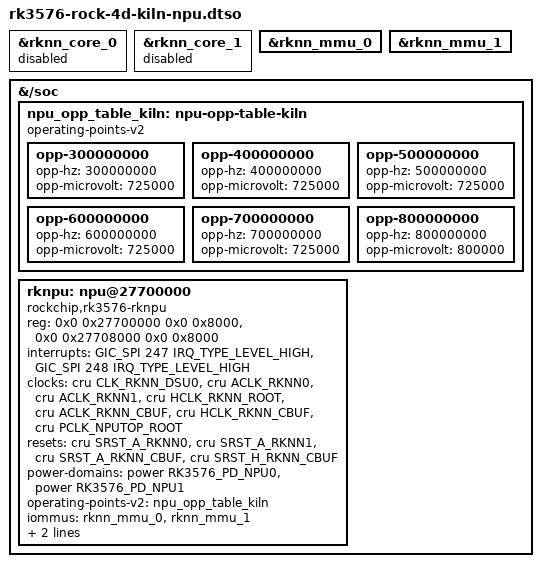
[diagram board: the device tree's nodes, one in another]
// SPDX-License-Identifier: (GPL-2.0-only OR MIT)
/*
 * Kiln NPU overlay for Radxa ROCK 4D (RK3576) on a mainline / Armbian kernel.
 *
 * Turns the board's open "rocket" NPU (rknn_core_0/1) OFF and adds the single
 * vendor-shaped npu@27700000 that the out-of-tree vendor rknpu (v0.9.8) driver
 * binds, so librkllmrt / RKLLM can run LLMs on the NPU. It REUSES the base DT's
 * rknn_mmu_0/1 IOMMU nodes (same hardware, same clocks/power-domain as the
 * vendor MMUs) instead of declaring duplicates.
 *
 * Build:  dtc -@ -I dts -O dtb -o rk3576-rock-4d-kiln-npu.dtbo \
 *              rk3576-rock-4d-kiln-npu.dtso    (cpp-preprocessed for the headers)
 * Armbian: copy the .dtbo to /boot/dtb/rockchip/overlay/ (or /boot/overlay-user/)
 *          and add its name to `user_overlays=` in /boot/armbianEnv.txt.
 *
 * Requires: the base DT to expose the labels &rknn_core_0/1, &rknn_mmu_0/1,
 * &cru, &power, &vdd_npu_s0 (mainline rk3576.dtsi + rk3576-rock-4d.dts do).
 */
/dts-v1/;
/plugin/;

#include <dt-bindings/clock/rockchip,rk3576-cru.h>
#include <dt-bindings/interrupt-controller/arm-gic.h>
#include <dt-bindings/interrupt-controller/irq.h>
#include <dt-bindings/power/rockchip,rk3576-power.h>
#include <dt-bindings/reset/rockchip,rk3576-cru.h>

/* Turn the open rocket NPU cores off; the vendor rknpu drives this hardware. */
&rknn_core_0 { status = "disabled"; };
&rknn_core_1 { status = "disabled"; };

/* Reuse the base MMU nodes as the vendor NPU's two IOMMUs (one per core). */
&rknn_mmu_0 { status = "okay"; };
&rknn_mmu_1 { status = "okay"; };

&{/soc} {
	npu_opp_table_kiln: npu-opp-table-kiln {
		compatible = "operating-points-v2";
		opp-300000000 { opp-hz = /bits/ 64 <300000000>; opp-microvolt = <725000>; };
		opp-400000000 { opp-hz = /bits/ 64 <400000000>; opp-microvolt = <725000>; };
		opp-500000000 { opp-hz = /bits/ 64 <500000000>; opp-microvolt = <725000>; };
		opp-600000000 { opp-hz = /bits/ 64 <600000000>; opp-microvolt = <725000>; };
		opp-700000000 { opp-hz = /bits/ 64 <700000000>; opp-microvolt = <725000>; };
		opp-800000000 { opp-hz = /bits/ 64 <800000000>; opp-microvolt = <800000>; };
	};

	rknpu: npu@27700000 {
		compatible = "rockchip,rk3576-rknpu";
		reg = <0x0 0x27700000 0x0 0x8000>,
		      <0x0 0x27708000 0x0 0x8000>;
		interrupts = <GIC_SPI 247 IRQ_TYPE_LEVEL_HIGH>,
			     <GIC_SPI 248 IRQ_TYPE_LEVEL_HIGH>;
		interrupt-names = "npu0_irq", "npu1_irq";
		clocks = <&cru CLK_RKNN_DSU0>, <&cru ACLK_RKNN0>,
			 <&cru ACLK_RKNN1>, <&cru HCLK_RKNN_ROOT>,
			 <&cru ACLK_RKNN_CBUF>, <&cru HCLK_RKNN_CBUF>,
			 <&cru PCLK_NPUTOP_ROOT>;
		clock-names = "clk_npu", "aclk0", "aclk1", "hclk_root",
			      "aclk_cbuf", "hclk_cbuf", "pclk";
		resets = <&cru SRST_A_RKNN0>, <&cru SRST_A_RKNN1>,
			 <&cru SRST_A_RKNN_CBUF>, <&cru SRST_H_RKNN_CBUF>;
		reset-names = "srst_a0", "srst_a1",
			      "srst_a_cbuf", "srst_h_cbuf";
		power-domains = <&power RK3576_PD_NPU0>, <&power RK3576_PD_NPU1>;
		power-domain-names = "npu0", "npu1";
		operating-points-v2 = <&npu_opp_table_kiln>;
		iommus = <&rknn_mmu_0>, <&rknn_mmu_1>;
		npu-supply = <&vdd_npu_s0>;
		#cooling-cells = <2>;
		dynamic-power-coefficient = <2570>;
		status = "okay";
	};
};
